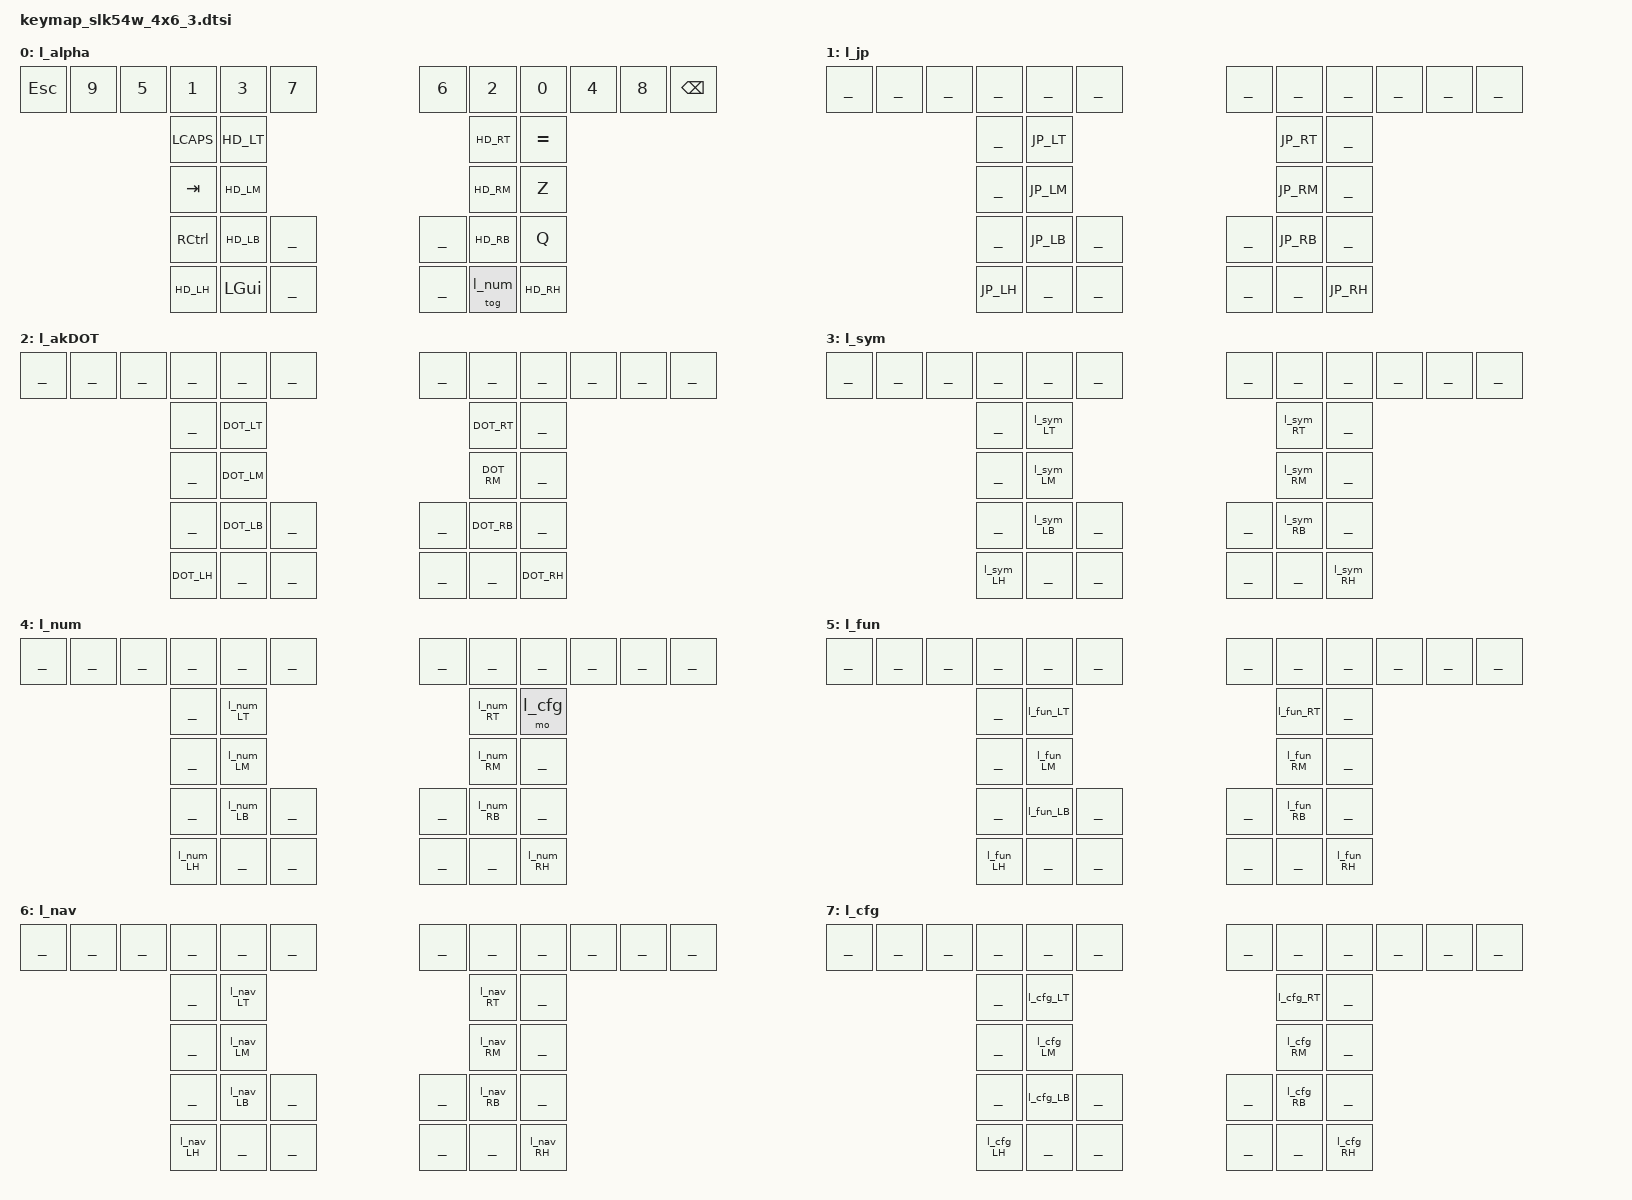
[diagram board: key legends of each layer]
/*
    Assemble the keymap from the abstracted alpha layer and other layers

    This is for a Silakka54 wireless (3x5+3) board (modified from Lily58)

    Uses the core 3x5+2 alpha row defs and adds extra keys to fill out the keymap.
    The key (rows) values are defined in the corresponding HD-##.h file
    that should be included in the .keymap file before this.

    Layers are defined in moutis_config.dtsi so they can be
    referenced anywhere (keymap, behaviors, combos, adaptives)

*/

#include "layers_def.h" // layer def common core (3x5+2)


    keymap {
        compatible = "zmk,keymap";
            l_alpha {
                label = HD_Layer_label;
                bindings = <
//                  0     1   2   3   4  5                        6   7   8   9  10    11
//                    ╭─────────────────────╮                  ╭─────────────────────╮
//                 12 │  13  14  15  16  17 │                  │ 18  19  20  21  22  │ 23
//                 24 │  25  26  27  28  29 │                  │ 30  31  32  33  34  │ 35
//                 36 │  37  38  39  40  41 │                  │ 42  43  44  45  46  │ 47
//                    ╰────────╮ 48  49  50 │                  │ 51  52  53 ╭────────╯
//                             ╰────────────╯                  ╰────────────╯
//
//                 NRA   NR1 NR2 NR3 NR4 NR5                      NR6 NR7 NR8 NR9 NR0   NRB
//                     ╭─────────────────────╮                  ╭─────────────────────╮
//                 LT5 │ LT4 LT3 LT2 LT1 LT0 │                  │ RT0 RT1 RT2 RT3 RT4 │ RT5
//                 LM5 │ LM4 LM3 LM2 LM1 LM0 │                  │ RM0 RM1 RM2 RM3 RM4 │ RM5
//                 LB5 │ LB4 LB3 LB2 LB1 LB0 │ LBA          RBA │ RB0 RB1 RB2 RB3 RB4 │ RB5
//                     ╰────────╮LH2 LH1 LH0 │ LHA          RHA │ RH0 RH1 RH2╭────────╯
//                 LH5  LH4 LH3 ╰────────────╯                  ╰────────────╯ RH3 RH4  LH5
//
//                     ESC      9   5   1   3   7       6    2   0   4   8    BKSP
//                           ╭─────────────────────╮ ╭──────────────────────╮
//                     CPSL  │  X   W   M   G   J  │ │  #$  .:  /*  "<  '>  │
//                     TAB   │  S   C   N   T   K  | |  ,;   A   E   I   H  │ Z
//                     CTRL  │  F   P   L   D   V  │ │  -+   U   O   Y   B  │ Q
//                           ╰──────────╮  BSP  R  │ │  SPC RET  ╭──────────╯
//                                      ╰──────────╯ ╰───────────╯
 &kp ESC   &kp N9 &kp N5 &kp N1   &kp N3   &kp N7                       &kp N6 &kp N2   &kp N0    &kp N4  &kp N8   &kp BACKSPACE
                             &kp LCAPS     HD_LT                        HD_RT       &kp EQUAL
                             &kp TAB       HD_LM                        HD_RM       &kp Z
                             &kp RCTRL     HD_LB    _______  _______    HD_RB       &kp Q
                             HD_LH         &kp LGUI _______  _______    &tog l_num  HD_RH
                >;
            };

            l_jp {
                label = JP_Layer_label;
                bindings = <
            _______ _______ _______ _______ _______ _______  _______ _______ _______ _______ _______ _______
                             _______      JP_LT                        JP_RT    _______
                             _______      JP_LM                        JP_RM    _______
                             _______      JP_LB    _______  _______    JP_RB    _______
                             JP_LH      _______    _______  _______    _______    JP_RH
                >;
            };

            l_akDOT {
                label = l_akDOT_label;
                bindings = <
            _______ _______ _______ _______ _______ _______  _______ _______ _______ _______ _______ _______
                             _______      DOT_LT                        DOT_RT    _______
                             _______      DOT_LM                        DOT_RM    _______
                             _______      DOT_LB    _______  _______    DOT_RB    _______
                             DOT_LH      _______    _______  _______    _______    DOT_RH
                >;
            };

            l_sym {
                label = l_sym_label;
                bindings = <
            _______ _______ _______ _______ _______ _______  _______ _______ _______ _______ _______ _______
                             _______    l_sym_LT                        l_sym_RT    _______
                             _______    l_sym_LM                        l_sym_RM    _______
                             _______    l_sym_LB    _______  _______    l_sym_RB    _______
                             l_sym_LH    _______    _______  _______    _______    l_sym_RH
                >;
            };

            l_num {
                label = l_num_label;
                bindings = <
            _______ _______ _______ _______ _______ _______  _______ _______ _______ _______ _______ _______
                             _______    l_num_LT                        l_num_RT    &mo l_cfg
                             _______    l_num_LM                        l_num_RM    _______
                             _______    l_num_LB    _______  _______    l_num_RB    _______
                             l_num_LH    _______    _______  _______    _______    l_num_RH
                >;
            };

            l_fun {
                label = l_fun_label;
                bindings = <
            _______ _______ _______ _______ _______ _______  _______ _______ _______ _______ _______ _______
                             _______    l_fun_LT                        l_fun_RT    _______
                             _______    l_fun_LM                        l_fun_RM    _______
                             _______    l_fun_LB    _______  _______    l_fun_RB    _______
                             l_fun_LH    _______    _______  _______    _______    l_fun_RH
                >;
            };

            l_nav {
                label = l_nav_label;
                bindings = <
            _______ _______ _______ _______ _______ _______  _______ _______ _______ _______ _______ _______
                             _______    l_nav_LT                        l_nav_RT    _______
                             _______    l_nav_LM                        l_nav_RM    _______
                             _______    l_nav_LB    _______  _______    l_nav_RB    _______
                             l_nav_LH    _______    _______  _______    _______    l_nav_RH
                >;
            };

            l_cfg {
                label = l_cfg_label;
                bindings = <
            _______ _______ _______ _______ _______ _______  _______ _______ _______ _______ _______ _______
                             _______    l_cfg_LT                        l_cfg_RT    _______
                             _______    l_cfg_LM                        l_cfg_RM    _______
                             _______    l_cfg_LB    _______  _______    l_cfg_RB    _______
                             l_cfg_LH    _______    _______  _______    _______    l_cfg_RH
                >;
            };
    };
